# STM32H745_CM7 register map
File version: 2.0
CPU: CM7 r0p1, little endian, MPU, FPU, 4 interrupt priority bits
Registers are 32-bit, read-write, reset 0x0 unless marked. A register's access mark holds for its fields unless they carry their own. Offsets are from the block's base; [hi:lo] are bit positions; {n}, {i} and the like mark numbered series; 'fields as' and 'values as' point back to an identical list.

## HSEM
Base 0x58026400
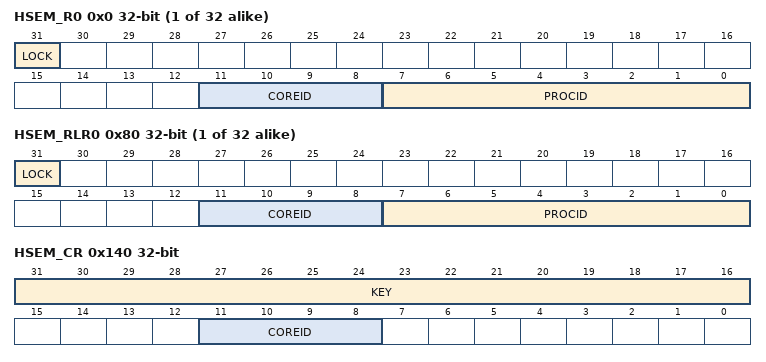
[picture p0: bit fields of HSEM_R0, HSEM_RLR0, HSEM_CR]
{0x0+4i} HSEM_R{i} (i=0..31) — HSEM register HSEM_R0 HSEM_R31
  [31] LOCK — Lock indication
  [11:8] COREID — Semaphore COREID
  [7:0] PROCID — Semaphore ProcessID
{0x80+4i} HSEM_RLR{i} ro (i=0..31) — HSEM Read lock register
  fields as HSEM_R0
0x100 HSEM_C1IER — HSEM Interrupt enable register
  [31:0] ISE — Interrupt semaphore x enable bit
0x104 HSEM_C1ICR — HSEM Interrupt clear register
  [31:0] ISC — Interrupt semaphore x clear bit
0x108 HSEM_C1ISR ro — HSEM Interrupt status register
  [31:0] ISF — Interrupt semaphore x status bit before enable (mask)
0x10C HSEM_C1MISR ro — HSEM Masked interrupt status register
  [31:0] MISF — masked interrupt semaphore x status bit after enable (mask)
0x110 HSEM_C2IER — HSEM Interrupt enable register
  [31:0] ISE — Interrupt semaphore x enable bit
0x114 HSEM_C2ICR — HSEM Interrupt clear register
  [31:0] ISC — Interrupt semaphore x clear bit
0x118 HSEM_C2ISR ro — HSEM Interrupt status register
  [31:0] ISF — Interrupt semaphore x status bit before enable (mask)
0x11C HSEM_C2MISR ro — HSEM Masked interrupt status register
  fields as HSEM_C1MISR
0x140 HSEM_CR wo — HSEM Clear register
  [31:16] KEY — Semaphore clear Key
  [11:8] COREID — COREID of semaphores to be cleared
0x144 HSEM_KEYR — HSEM Interrupt clear register
  [31:16] KEY — Semaphore Clear Key

## RNG
Base 0x48021800
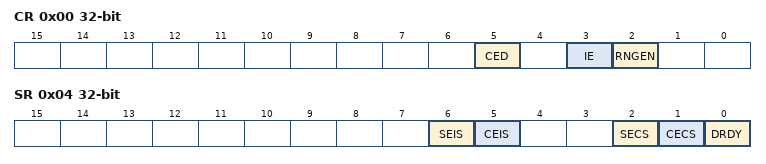
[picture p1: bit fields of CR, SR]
0x00 CR — RNG control register
  [5] CED — Clock error detection Note: The clock error detection can be used only when ck_rc48 or ck_pll1_q (ck_pll1_q = 48MHz) source is selected otherwise, CED bit must be equal to 1. The clock error detection cannot be enabled nor disabled on the fly when RNG peripheral is enabled, to enable or disable CED the RNG must be disabled.
  [3] IE — Interrupt enable
  [2] RNGEN — Random number generator enable
0x04 SR access per field — RNG status register
  [6] SEIS rw — Seed error interrupt status This bit is set at the same time as SECS. It is cleared by writing it to 0. ** More than 64 consecutive bits at the same value (0 or 1) ** More than 32 consecutive alternances of 0 and 1 (0101010101...01) An interrupt is pending if IE = 1 in the RNG_CR register.
  [5] CEIS rw — Clock error interrupt status This bit is set at the same time as CECS. It is cleared by writing it to 0. An interrupt is pending if IE = 1 in the RNG_CR register. Note: This bit is meaningless if CED (Clock error detection) bit in RNG_CR is equal to 1.
  [2] SECS ro — Seed error current status ** More than 64 consecutive bits at the same value (0 or 1) ** More than 32 consecutive alternances of 0 and 1 (0101010101...01)
  [1] CECS ro — Clock error current status Note: This bit is meaningless if CED (Clock error detection) bit in RNG_CR is equal to 1.
  [0] DRDY ro — Data ready Note: If IE=1 in RNG_CR, an interrupt is generated when DRDY=1. It can rise when the peripheral is disabled. When the output buffer becomes empty (after reading RNG_DR), this bit returns to 0 until a new random value is generated.
0x08 DR ro — The RNG_DR register is a read-only register that delivers a 32-bit random value when read. The content of this register is valid when DRDY= 1, even if RNGEN=0.
  [31:0] RNDATA — Random data 32-bit random data which are valid when DRDY=1.

## VREFBUF
Base 0x58003C00
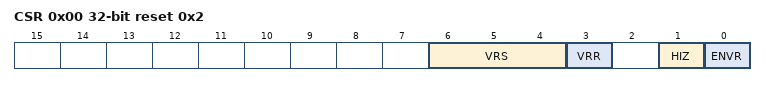
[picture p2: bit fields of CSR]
0x00 CSR access per field reset 0x2 — VREFBUF control and status register
  [6:4] VRS rw — Voltage reference scale These bits select the value generated by the voltage reference buffer. Other: Reserved
  [3] VRR ro — Voltage reference buffer ready
  [1] HIZ rw — High impedance mode This bit controls the analog switch to connect or not the VREF+ pin. Refer to Table196: VREF buffer modes for the mode descriptions depending on ENVR bit configuration.
  [0] ENVR rw — Voltage reference buffer mode enable This bit is used to enable the voltage reference buffer mode.
0x04 CCR — VREFBUF calibration control register
  [5:0] TRIM — Trimming code These bits are automatically initialized after reset with the trimming value stored in the Flash memory during the production test. Writing into these bits allows to tune the internal reference buffer voltage.

## Notices in the file
Copyright (c) 2023 STMicroelectronics.
SPDX-License-Identifier: Apache-2.0
Licensed under the Apache License, Version 2.0 (the "License");
you may not use this file except in compliance with the License.
You may obtain a copy of the License at
http://www.apache.org/licenses/LICENSE-2.0
Unless required by applicable law or agreed to in writing, software
distributed under the License is distributed on an "AS IS" BASIS,
WITHOUT WARRANTIES OR CONDITIONS OF ANY KIND, either express or implied.
See the License for the specific language governing permissions and
limitations under the License.
